# R7FA8M1AH register map
Vendor: Renesas; Series: RA8; File version: 1.2
CPU: CM85 r0p0, little endian, MPU, FPU, VTOR, 4 interrupt priority bits
Registers are 32-bit, read-write, reset 0x0 unless marked. A register's access mark holds for its fields unless they carry their own. Offsets are from the block's base; [hi:lo] are bit positions; {n}, {i} and the like mark numbered series.

## TZF — TrustZone Filter
Base 0x40004000
Same registers: TZF_NS 0x50004000
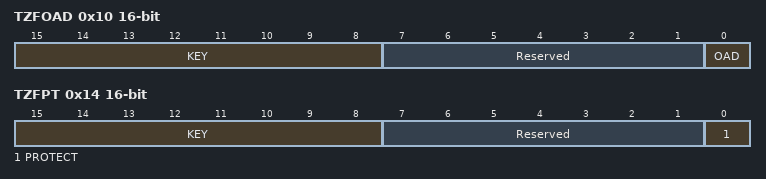
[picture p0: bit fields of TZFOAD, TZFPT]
0x10 TZFOAD 16-bit — TrustZone Filter Operation After Detection register
  [15:8] KEY wo — Key Code
  [7:1] Reserved — These bits are read as 0000000. The write value should be 0000000.
  [0] OAD — Operation after detection
    0=Only error response is returned; 1=Reset; 0=NMI; 1=Reset
0x14 TZFPT 16-bit — TrustZone Filter Protect register
  [15:8] KEY wo — Key Code
  [7:1] Reserved — These bits are read as 0000000. The write value should be 0000000.
  [0] PROTECT — Protection of register
    0=TZFOAD register writing is possible; 1=TZFOAD register writing is protected. Read is possible.

## ICU_COMMON — Common Interrupt Controller
Base 0x40006000
Same registers: ICU_COMMON_NS 0x50006000
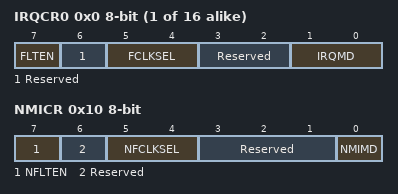
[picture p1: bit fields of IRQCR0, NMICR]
{0x0+i} IRQCR{i} (i=0..15) 8-bit — IRQ Control Register {i}
  [7] FLTEN — IRQ Digital Filter Enable
    0=Digital filter is disabled; 1=Digital filter is enabled
  [6] Reserved — This bit is read as 0. The write value should be 0.
  [5:4] FCLKSEL — IRQ Digital Filter Sampling Clock Select
    0=PCLKB; 1=PCLKB/8; 2=PCLKB/32; 3=PCLKB/64
  [3:2] Reserved — These bits are read as 00. The write value should be 00.
  [1:0] IRQMD — IRQ Detection Sense Select
    0=Falling edge; 1=Rising edge; 2=Rising and falling edges; 3=Low level
0x10 NMICR 8-bit — NMI Pin Interrupt Control Register
  [7] NFLTEN — NMI Digital Filter Enable
    0=Digital filter is disabled; 1=Digital filter is enabled
  [6] Reserved — This bit is read as 0. The write value should be 0.
  [5:4] NFCLKSEL — NMI Digital Filter Sampling Clock
    0=PCLKB; 1=PCLKB/8; 2=PCLKB/32; 3=PCLKB/64
  [3:1] Reserved — These bits are read as 000. The write value should be 000.
  [0] NMIMD — NMI Detection Set
    0=Falling edge; 1=Rising edge

## DMA — DMAC Module Activation
Base 0x4000A800
Same registers: DMA_NS 0x5000A800
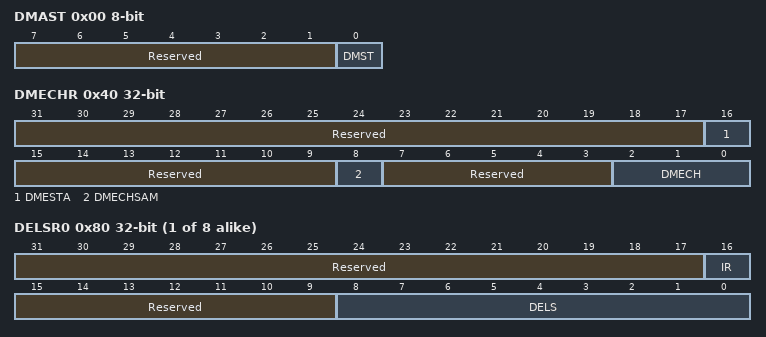
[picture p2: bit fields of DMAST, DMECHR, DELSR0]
0x00 DMAST 8-bit — DMA Module Activation Register
  [7:1] Reserved — These bits are read as 0000000. The write value should be 0000000.
  [0] DMST — DMAC Operation Enable
    0=DMAC activation is disabled; 1=DMAC activation is enabled
0x40 DMECHR — DMACA Error Channel Register
  [31:17] Reserved — These bits are read as 000000000000000. The write value should be 000000000000000.
  [16] DMESTA — DMAC Error Status
    0=No DMA transfer error occurred; 1=DMA transfer error occurred
  [15:9] Reserved — These bits are read as 0000000. The write value should be 0000000.
  [8] DMECHSAM — DMAC Error channel SA Monitor
  [7:3] Reserved — These bits are read as 00000. The write value should be 00000.
  [2:0] DMECH — DMAC Error channel
{0x80+4i} DELSR{i} (i=0..7) (reset mask 0xFFFF) — DMAC Event Link Setting Register {i}
  [31:17] Reserved — These bits are read as 000000000000000. The write value should be 000000000000000.
  [16] IR — DMAC Activation Request Status flag
    0=No DMAC activation request occurred; 1=DMAC activation request occurred. ( "1" write to the IR bit is prohibited. )
  [15:9] Reserved — These bits are read as 0000000. The write value should be 0000000.
  [8:0] DELS — DMAC Event Link Select
    0=Disable interrupts to the associated DMAC module; other=others (Event signal number to be linked.)

## DTC — Data Transfer Controller
Base 0x4000AC00
Same registers: DTC_NS 0x5000AC00
0x00 DTCCR 8-bit reset 0x8 (alternate view of DTCCR_NS) — DTC Control Register
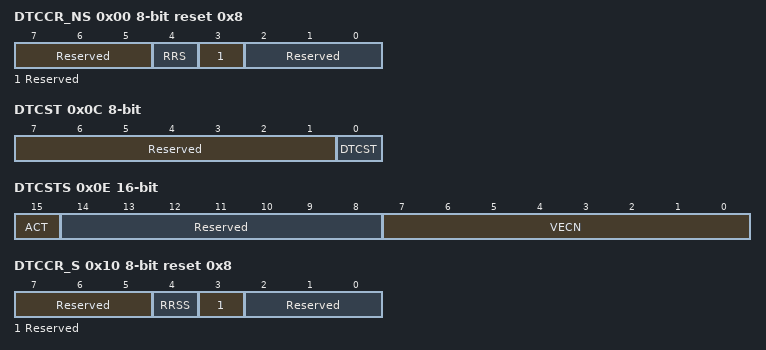
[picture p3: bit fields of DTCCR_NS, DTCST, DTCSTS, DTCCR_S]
0x00 DTCCR_NS 8-bit reset 0x8 — DTC Control Register for Non Secure Region
  [7:5] Reserved — These bits are read as 000. The write value should be 000.
  [4] RRS — DTC Transfer Information Read Skip Enable.
    0=Do not skip transfer information read; 1=Skip transfer information read when vector numbers match
  [3] Reserved — This bit is read as 1. The write value should be 1.
  [2:0] Reserved — These bits are read as 000. The write value should be 000.
0x04 DTCVBR (alternate view of DTCVBR_NS) — DTC Vector Base Register
0x04 DTCVBR_NS — DTC Vector Base Register for Non Secure Region
  [31:10] DTCVBR — DTC Vector Base Address for non-secure region(Upper 22 bits)
0x0C DTCST 8-bit — DTC Module Start Register
  [7:1] Reserved — These bits are read as 0000000. The write value should be 0000000.
  [0] DTCST — DTC Module Start
    0=DTC module stop; 1=DTC module start
0x0E DTCSTS 16-bit ro — DTC Status Register
  [15] ACT — DTC Active Flag
    0=DTC transfer operation is not in progress; 1=DTC transfer operation is in progress
  [14:8] Reserved — These bits are read as 0000000.
  [7:0] VECN — DTC-Activating Vector Number MonitoringThese bits indicate the vector number for the activating source when DTC transfer is in progress.The value is only valid if DTC transfer is in progress (the value of the ACT flag is 1)
0x10 DTCCR_S 8-bit reset 0x8 — DTC Control Register for Secure Region
  [7:5] Reserved — These bits are read as 000. The write value should be 000.
  [4] RRSS — DTC Transfer Information Read Skip Enable for secure
    0=Transfer information read is not skipped; 1=Transfer information read is skipped when vector numbers match
  [3] Reserved — This bit is read as 1. The write value should be 1.
  [2:0] Reserved — These bits are read as 000. The write value should be 000.
0x10 DTCCR_SEC 8-bit reset 0x8 (alternate view of DTCCR_S) — DTC Control Register for Secure Region
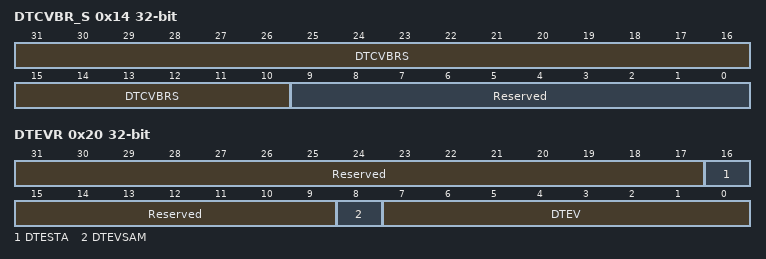
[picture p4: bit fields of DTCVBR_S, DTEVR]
0x14 DTCVBR_S — DTC Vector Base Register for secure Region
  [31:10] DTCVBRS — DTC Vector Base Address for secure region(Upper 22 bits)
  [9:0] Reserved — These bits are read as 0000000000. The write value should be 0000000000.
0x14 DTCVBR_SEC (alternate view of DTCVBR_S) — DTC Vector Base Register for secure Region
0x20 DTEVR — DTC Error Vector Register
  [31:17] Reserved — These bits are read as 000000000000000. The write value should be 000000000000000.
  [16] DTESTA — DTC Error Status Flag
    0=Not DTC transfer error occurred; 1=DMA transfer error occurred
  [15:9] Reserved — These bits are read as 0000000. The write value should be 0000000.
  [8] DTEVSAM ro — DTC Error Vector Number SA Monitor
  [7:0] DTEV ro — DTC Error Vector Number
